# pse84_a0 register map
Vendor: Infineon Technologies; Series: PSE84_A0; File version: 1.0
CPU: CM33 r0p1, little endian, MPU, FPU, VTOR, 3 interrupt priority bits
Registers are 32-bit, read-write, reset 0x0 unless marked. A register's access mark holds for its fields unless they carry their own. Offsets are from the block's base; [hi:lo] are bit positions; lines under a group give offsets from that group; {n}, {i} and the like mark numbered series; 'fields as' and 'values as' point back to an identical list; <NAME> marks a mode.

## USBHS (part 6 of 7) — Regmap for both Subsystem and Controller IP
Base 0x44900000
0x00 DWC_OTG_INTREG group — Internal register map
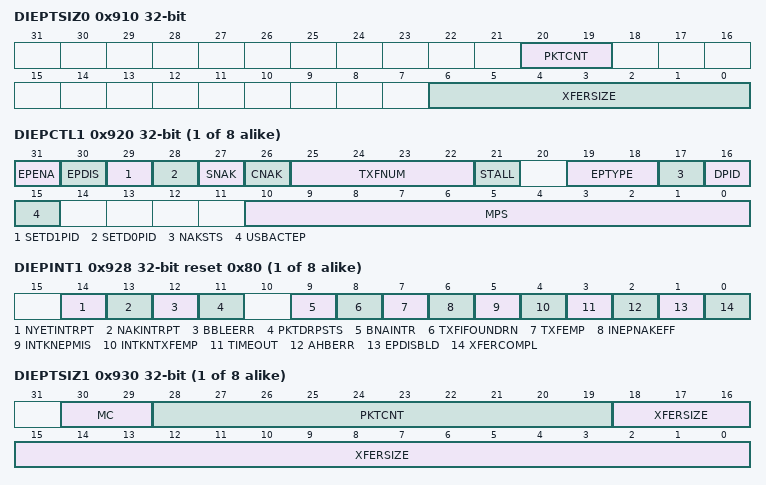
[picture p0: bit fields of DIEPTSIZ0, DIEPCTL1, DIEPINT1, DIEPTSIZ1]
  0x910 DIEPTSIZ0 — The application must modify this register before enabling endpoint 0. Once endpoint 0 is enabled using Endpoint Enable bit of the Device Control Endpoint 0 Control registers (DIEPCTL0.EPEna/DOEPCTL0.EPEna), the core modifies this register. The application can only read this register once the core has cleared the Endpoint Enable bit. Nonzero endpoints use the registers for endpoints 115. When Scatter/Gather DMA mode is enabled, this register must not be programmed by the application. If the application reads this register when Scatter/Gather DMA mode is enabled, the core returns all zeros.
    [20:19] PKTCNT — Packet Count (PktCnt) Indicates the total number of USB packets that constitute the Transfer Size amount of data for endpoint 0. - IN Endpoints : This field is decremented every time a packet (maximum size or short packet) is read from the TxFIFO. - OUT Endpoints: This field is decremented every time a packet (maximum size or short packet) is written to the RxFIFO.
    [6:0] XFERSIZE — Transfer Size (XferSize) This field contains the transfer size in bytes for the current endpoint. The transfer size (XferSize) = Sum of buffer sizes across all descriptors in the list for the endpoint. In Buffer DMA, the core only interrupts the application after it has exhausted the transfer size amount of data. The transfer size can be set to the maximum packet size of the endpoint, to be interrupted at the end of each packet. - IN Endpoints: The core decrements this field every time a packet from the external memory is written to the TxFIFO. - OUT Endpoints: The core decrements this field every time a packet is read from the RxFIFO and written to the external memory.
  0x914 DIEPDMA0 reset not defined — This register contains the DMA Address for the IN Endpoint 0 of the Device controller.
    [31:0] DMAADDR — DMAAddr This field holds the start address of the external memory for storing or fetching endpoint data. Note: For control endpoints, this field stores control OUT data packets as well as SETUP transaction data packets. When more than three SETUP packets are received back-to-back, the SETUP data packet in the memory is overwritten. This register is incremented on every AHB transaction. The application can give only a DWORD-aligned address. When Scatter/Gather DMA mode is not enabled, the application programs the start address value in this field. When Scatter/Gather DMA mode is enabled, this field indicates the base pointer for the descriptor list.
  0x918 DTXFSTS0 ro reset 0x100 — This register contains information about the IN Endpoint Transmit FIFO of the Device controller.
    [15:0] INEPTXFSPCAVAIL
  0x91C DIEPDMAB0 ro reset not defined — This register contains the DMA Buffer Address for the IN Endpoint 0 of the Device controller.
    [31:0] DMABUFFERADDR
  {0x900+0x20*j} DIEPCTL{j} (j=1..8) — This register is used to control the characteristics of Endpoint {j}. Note: This register exists for an endpoint i if the OTG_EP_DIR_i parameter is 0 or 1 for that endpoint.
    [31] EPENA — Endpoint Enable (EPEna) Applies to IN and OUT endpoints. - When Scatter/Gather DMA mode is enabled, -- For IN endpoints this bit indicates that the descriptor structure and data buffer with data ready to transmit is setup. -- For OUT endpoint it indicates that the descriptor structure and data buffer to receive data is setup. - When Scatter/Gather DMA mode is enabled such as for buffer-pointer based DMA mode: -- For IN endpoints, this bit indicates that data is ready to be transmitted on the endpoint. -- For OUT endpoints, this bit indicates that the application has allocated the memory to start receiving data from the USB. - The core clears this bit before setting any of the following interrupts on this endpoint: -- SETUP Phase Done -- Endpoint Disabled -- Transfer Completed Note: For control endpoints in DMA mode, this bit must be set to be able to transfer SETUP data packets in memory.
      1=ACTIVE (Enable Endpoint); 0=INACTIVE (No Action)
    [30] EPDIS — Endpoint Disable (EPDis) Applies to IN and OUT endpoints. The application sets this bit to stop transmitting/receiving data on an endpoint, even before the transfer for that endpoint is complete. The application must wait for the Endpoint Disabled interrupt before treating the endpoint as disabled. The core clears this bit before setting the Endpoint Disabled interrupt. The application must set this bit only if Endpoint Enable is already set for this endpoint.
      1=ACTIVE (Disable Endpoint); 0=INACTIVE (No Action)
    [29] SETD1PID wo — SetD1PID - Set DATA1 PID (SetD1PID) -- Applies to interrupt and bulk IN and OUT endpoints only. -- Writing to this field sets the Endpoint Data PID (DPID) field in this register to DATA1. -- This field is applicable both for Scatter-Gather DMA mode and non Scatter-Gather DMA mode. - Set odd (micro)Frame (SetOddFr) -- Applies to isochronous IN and OUT endpoints only. -- Writing to this field sets the even and odd (micro)Frame (EO_FrNum) field to odd (micro)Frame. -- This field is not applicable for Scatter-Gather DMA mode.
      0=DISABLED (Disables Set DATA1 PID); 1=ENABLED (Enables Set DATA1 PID)
    [28] SETD0PID wo
      0=DISABLED (Disables Set DATA0 PID); 1=ENABLED (Endpoint Data PID to DATA0))
    [27] SNAK wo — Set NAK (SNAK) A write to this bit sets the NAK bit for the endpoint. Using this bit, the application can control the transmission of NAK handshakes on an endpoint. The core can also Set this bit for an endpoint after a SETUP packet is received on that endpoint.
      1=ACTIVE (Set NAK); 0=INACTIVE (No Set NAK)
    [26] CNAK wo — Clear NAK (CNAK) A write to this bit clears the NAK bit for the endpoint.
      1=ACTIVE (Clear NAK); 0=INACTIVE (No Clear NAK)
    [25:22] TXFNUM — TxFIFO Number (TxFNum) Shared FIFO Operation non-periodic endpoints must set this bit to zero. Periodic endpoints must map this to the corresponding Periodic TxFIFO number. - 4'h0: Non-Periodic TxFIFO - Others: Specified Periodic TxFIFO.number Note: An interrupt IN endpoint can be configured as a non-periodic endpoint for applications such as mass storage. The core treats an IN endpoint as a non-periodic endpoint if the TxFNum field is set to 0. Otherwise, a separate periodic FIFO must be allocated for an interrupt IN endpoint, and the number of this FIFO must be programmed into the TxFNum field. Configuring an interrupt IN endpoint as a non-periodic endpoint saves the extra periodic FIFO area. Dedicated FIFO Operation: These bits specify the FIFO number associated with this endpoint. Each active IN endpoint must be programmed to a separate FIFO number. This field is valid only for IN endpoints.
      {v}=TXFIFO{v} (v=0..15)
    [21] STALL — STALL Handshake (Stall) Applies to non-control, non-isochronous IN and OUT endpoints only. The application sets this bit to stall all tokens from the USB host to this endpoint. If a NAK bit, Global Non-periodic IN NAK, or Global OUT NAK is set along with this bit, the STALL bit takes priority. Only the application can clear this bit, never the core. Applies to control endpoints only. The application can only set this bit, and the core clears it, when a SETUP token is received for this endpoint. If a NAK bit, Global Non-periodic IN NAK, or Global OUT NAK is set along with this bit, the STALL bit takes priority. Irrespective of this bit's setting, the core always responds to SETUP data packets with an ACK handshake.
      1=ACTIVE (STALL All Active Tokens); 0=INACTIVE (STALL All non-active tokens)
    [19:18] EPTYPE — Endpoint Type (EPType) This is the transfer type supported by this logical endpoint. - 2'b00: Control - 2'b01: Isochronous - 2'b10: Bulk - 2'b11: Interrupt
      2=BULK; 0=CONTROL; 3=INTERRUP (Interrupt); 1=ISOCHRONOUS
    [17] NAKSTS ro — NAK Status (NAKSts) Indicates the following: - 1'b0: The core is transmitting non-NAK handshakes based on the FIFO status. - 1'b1: The core is transmitting NAK handshakes on this endpoint. When either the application or the core sets this bit: - The core stops receiving any data on an OUT endpoint, even if there is space in the RxFIFO to accommodate the incoming packet. - For non-isochronous IN endpoints: The core stops transmitting any data on an IN endpoint, even if there data is available in the TxFIFO. - For isochronous IN endpoints: The core sends out a zero-length data packet, even if there data is available in the TxFIFO. Irrespective of this bit's setting, the core always responds to SETUP data packets with an ACK handshake.
      1=NAK (The core is transmitting NAK handshakes on this endpoint); 0=NONNAK (The core is transmitting non-NAK handshakes based on the FIFO status)
    [16] DPID ro
      0=DATA0EVENFRM (DATA0 or Even Frame); 1=DATA1ODDFRM (DATA1 or Odd Frame)
    [15] USBACTEP — USB Active Endpoint (USBActEP) Indicates whether this endpoint is active in the current configuration and interface. The core clears this bit for all endpoints (other than EP 0) after detecting a USB reset. After receiving the SetConfiguration and SetInterface commands, the application must program endpoint registers accordingly and set this bit.
      0=DISABLED (Not Active); 1=ENABLED (USB Active Endpoint)
    [10:0] MPS — Maximum Packet Size (MPS) The application must program this field with the maximum packet size for the current logical endpoint. This value is in bytes.
  {0x908+0x20*j} DIEPINT{j} reset 0x80 (j=1..8) — This register contains the interrupts for the IN Endpoint {j} of the Device controller. Note: This register exists for an endpoint i if the OTG_EP_DIR_i parameter is 0 or 1 for that endpoint.
    [14] NYETINTRPT — NYET Interrupt (NYETIntrpt) The core generates this interrupt when a NYET response is transmitted for a non isochronous OUT endpoint.
      1=ACTIVE (NYET Interrupt); 0=INACTIVE (No NYET interrupt)
    [13] NAKINTRPT — NAK Interrupt (NAKInterrupt) The core generates this interrupt when a NAK is transmitted or received by the device. In case of isochronous IN endpoints the interrupt gets generated when a zero length packet is transmitted due to un-availability of data in the TXFifo.
      1=ACTIVE (NAK Interrupt); 0=INACTIVE (No NAK interrupt)
    [12] BBLEERR — NAK Interrupt (BbleErr) The core generates this interrupt when babble is received for the endpoint.
      1=ACTIVE (BbleErr interrupt); 0=INACTIVE (No interrupt)
    [11] PKTDRPSTS — Packet Drop Status (PktDrpSts) This bit indicates to the application that an ISOC OUT packet has been dropped. This bit does not have an associated mask bit and does not generate an interrupt. Dependency: This bit is valid in non Scatter/Gather DMA mode when periodic transfer interrupt feature is selected.
      1=ACTIVE (Packet Drop Status interrupt); 0=INACTIVE (No interrupt)
    [9] BNAINTR — BNA (Buffer Not Available) Interrupt (BNAIntr) This bit is valid only when Scatter/Gather DMA mode is enabled. The core generates this interrupt when the descriptor accessed is not ready for the Core to process, such as Host busy or DMA done.
      1=ACTIVE (BNA interrupt); 0=INACTIVE (No BNA interrupt)
    [8] TXFIFOUNDRN — Fifo Underrun (TxfifoUndrn) Applies to IN endpoints Only This bit is valid only If thresholding is enabled. The core generates this interrupt when it detects a transmit FIFO underrun condition for this endpoint.
      1=ACTIVE (TxFIFO Underrun interrupt); 0=INACTIVE (No Tx FIFO Underrun interrupt)
    [7] TXFEMP ro — Transmit FIFO Empty (TxFEmp) This bit is valid only for IN endpoints This interrupt is asserted when the TxFIFO for this endpoint is either half or completely empty. The half or completely empty status is determined by the TxFIFO Empty Level bit in the Core AHB Configuration register (GAHBCFG.NPTxFEmpLvl)).
      1=ACTIVE (Transmit FIFO Empty interrupt); 0=INACTIVE (No Transmit FIFO Empty interrupt)
    [6] INEPNAKEFF — IN Endpoint NAK Effective (INEPNakEff) Applies to periodic IN endpoints only. This bit can be cleared when the application clears the IN endpoint NAK by writing to DIEPCTLn.CNAK. This interrupt indicates that the core has sampled the NAK bit Set (either by the application or by the core). The interrupt indicates that the IN endpoint NAK bit Set by the application has taken effect in the core. This interrupt does not guarantee that a NAK handshake is sent on the USB. A STALL bit takes priority over a NAK bit.
      1=ACTIVE (IN Endpoint NAK Effective interrupt); 0=INACTIVE (No Endpoint NAK Effective interrupt)
    [5] INTKNEPMIS — IN Token Received with EP Mismatch (INTknEPMis) Applies to non-periodic IN endpoints only. Indicates that the data in the top of the non-periodic TxFIFO belongs to an endpoint other than the one for which the IN token was received. This interrupt is asserted on the endpoint for which the IN token was received.
      1=ACTIVE (IN Token Received with EP Mismatch interrupt); 0=INACTIVE (No IN Token Received with EP Mismatch interrupt)
    [4] INTKNTXFEMP — IN Token Received When TxFIFO is Empty (INTknTXFEmp) Applies to non-periodic IN endpoints only. Indicates that an IN token was received when the associated TxFIFO (periodic/non-periodic) was empty. This interrupt is asserted on the endpoint for which the IN token was received.
      1=ACTIVE (IN Token Received Interrupt); 0=INACTIVE (No IN Token Received interrupt)
    [3] TIMEOUT — Timeout Condition (TimeOUT) - In shared TX FIFO mode, applies to non-isochronous IN endpoints only. - In dedicated FIFO mode, applies only to Control IN endpoints. - In Scatter/Gather DMA mode, the TimeOUT interrupt is not asserted. Indicates that the core has detected a timeout condition on the USB for the last IN token on this endpoint.
      1=ACTIVE (Timeout interrupt); 0=INACTIVE (No Timeout interrupt)
    [2] AHBERR — AHB Error (AHBErr) Applies to IN and OUT endpoints. This is generated only in Internal DMA mode when there is an AHB error during an AHB read/write. The application can read the corresponding endpoint DMA address register to get the error address. For details, see 'AHB Error Handling' in the Programming Guide.
      1=ACTIVE (AHB Error interrupt); 0=INACTIVE (No AHB Error Interrupt)
    [1] EPDISBLD — Endpoint Disabled Interrupt (EPDisbld) Applies to IN and OUT endpoints. This bit indicates that the endpoint is disabled per the application's request.
      1=ACTIVE (Endpoint Disabled Interrupt); 0=INACTIVE (No Endpoint Disabled Interrupt)
    [0] XFERCOMPL — Transfer Completed Interrupt (XferCompl) Applies to IN and OUT endpoints. - When Scatter/Gather DMA mode is enabled -- For IN endpoint this field indicates that the requested data from the descriptor is moved from external system memory to internal FIFO. -- For OUT endpoint this field indicates that the requested data from the internal FIFO is moved to external system memory. This interrupt is generated only when the corresponding endpoint descriptor is closed, and the IOC bit for the corresponding descriptor is set. - When Scatter/Gather DMA mode is disabled, this field indicates that the programmed transfer is complete on the AHB as well as on the USB, for this endpoint.
      1=ACTIVE (Transfer Complete Interrupt); 0=INACTIVE (No Transfer Complete Interrupt)
  {0x910+0x20*j} DIEPTSIZ{j} (j=1..8) — This register reflects the Transfer Size of the IN Endpoint {j} of the Device controller. Note: This register exists for an endpoint i if the OTG_EP_DIR_i parameter is 0 or 1 for that endpoint.
    [30:29] MC — MC Applies to IN endpoints only. For periodic IN endpoints, this field indicates the number of packets that must be transmitted per microframe on the USB. The core uses this field to calculate the data PID for isochronous IN endpoints. - 2'b01: 1 packet - 2'b10: 2 packets - 2'b11: 3 packets For non-periodic IN endpoints, this field is valid only in Internal DMA mode. It specifies the number of packets the core must fetchfor an IN endpoint before it switches to the endpoint pointed to by the Next Endpoint field of the Device Endpoint-n Control register (DIEPCTLn.NextEp)
      1=PACKETONE (1 packet); 3=PACKETTHREE (3 packets); 2=PACKETTWO (2 packets)
    [28:19] PKTCNT — Packet Count (PktCnt) Indicates the total number of USB packets that constitute the Transfer Size amount of data for endpoint 0. This field is decremented every time a packet (maximum size or short packet) is read from the TxFIFO.
    [18:0] XFERSIZE — Transfer Size (XferSize) Indicates the transfer size in bytes for endpoint 0. The core interrupts the application only after it has exhausted the transfer size amount of data. The transfer size can be Set to the maximum packet size of the endpoint, to be interrupted at the end of each packet. The core decrements this field every time a packet from the external memory is written to the TxFIFO.
  {0x914+0x20*j} DIEPDMA{j} reset not defined (j=1..8) — This register contains the DMA Address for the IN Endpoint {j} of the Device controller. Note: This register exists for an endpoint i if the OTG_EP_DIR_i parameter is 0 or 1 for that endpoint.
    [31:0] DMAADDR — Holds the start address of the external memory for storing or fetching endpoint data. Note: For control endpoints, this field stores control OUT data packets as well as SETUP transaction data packets. When more than three SETUP packets are received back-to-back, the SETUP data packet in the memory is overwritten. This register is incremented on every AHB transaction. The application can give only a DWORD-aligned address. - When Scatter/Gather DMA mode is not enabled, the application programs the start address value in this field. - When Scatter/Gather DMA mode is enabled, this field indicates the base pointer for the descriptor list.
  {0x918+0x20*j} DTXFSTS{j} ro reset 0x100 (j=1..8) — This register reflects the status of the IN Endpoint Transmit FIFO Status Register {j} of the Device controller. Note: This register exists for an endpoint i if the OTG_EP_DIR_i parameter is 0 or 1 for that endpoint.
    [15:0] INEPTXFSPCAVAIL
  {0x91C+0x20*j} DIEPDMAB{j} ro reset not defined (j=1..8) — This register contains the DMA Buffer Address of the IN Endpoint {j} of the Device controller. Note: This register exists for an endpoint i if the OTG_EP_DIR_i parameter is 0 or 1 for that endpoint.
    [31:0] DMABUFFERADDR
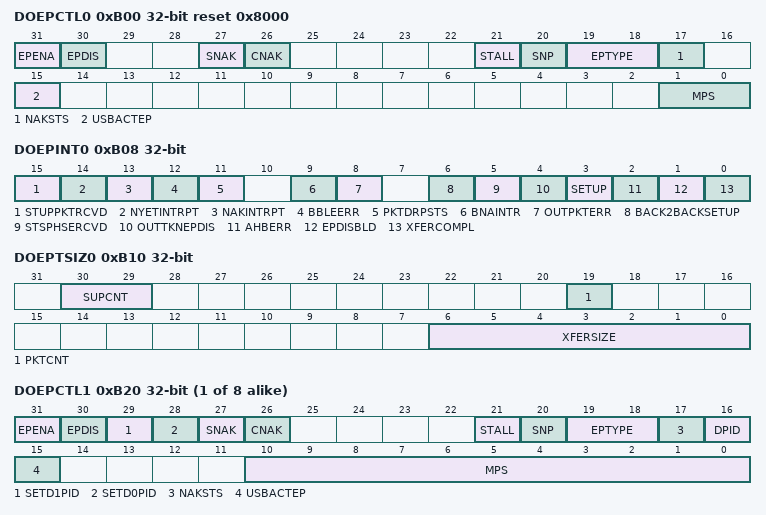
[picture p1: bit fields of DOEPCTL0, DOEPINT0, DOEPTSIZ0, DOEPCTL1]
  0xB00 DOEPCTL0 reset 0x8000 — This register is used to control the characteristics of the OUT Endpoint 0 of the Device controller.
    [31] EPENA — Endpoint Enable (EPEna) - When Scatter/Gather DMA mode is enabled, for OUT endpoints this bit indicates that the descriptor structure and data buffer to receive data is setup. - When Scatter/Gather DMA mode is disabled (such as for buffer-pointer based DMA mode)this bit indicates that the application has allocated the memory to start receiving data from the USB. - The core clears this bit before setting any of the following interrupts on this endpoint: -- SETUP Phase Done -- Endpoint Disabled -- Transfer Completed Note: In DMA mode, this bit must be set for the core to transfer SETUP data packets into memory and it will not be cleared on Transfer Completed interrupt of SETUP packet.
      1=ACTIVE (Enable Endpoint); 0=INACTIVE (No action)
    [30] EPDIS ro — Endpoint Disable (EPDis) The application cannot disable control OUT endpoint 0.
      0=INACTIVE (No Endpoint disable)
    [27] SNAK wo — Set NAK (SNAK) A write to this bit sets the NAK bit for the endpoint. Using this bit, the application can control the transmission of NAK handshakes on an endpoint. The core can also set bit on a Transfer Completed interrupt, or after a SETUP is received on the endpoint.
      0=NOSET (No action); 1=SET (Set NAK)
    [26] CNAK wo — Clear NAK (CNAK) A write to this bit clears the NAK bit for the endpoint.
      1=CLEAR (Clear NAK); 0=NOCLEAR (No action)
    [21] STALL — STALL Handshake (Stall) The application can only set this bit, and the core clears it, when a SETUP token is received for this endpoint. If a NAK bit or Global OUT NAK is Set along with this bit, the STALL bit takes priority. Irrespective of this bit's setting, the core always responds to SETUP data packets with an ACK handshake.
      1=ACTIVE (Stall Handshake); 0=INACTIVE (No Stall)
    [20] SNP
      0=RSVD0SnpDOEPCTL0 (N/A); 1=RSVD1SnpDOEPCTL0 (N/A)
    [19:18] EPTYPE ro — Endpoint Type (EPType) Hardcoded to 2'b00 for control.
      0=ACTIVE (Endpoint Control 0)
    [17] NAKSTS ro — NAK Status (NAKSts) Indicates the following: - 1'b0: The core is transmitting non-NAK handshakes based on the FIFO status. - 1'b1: The core is transmitting NAK handshakes on this endpoint. When either the application or the core sets this bit, the core stops receiving data, even If there is space in the RxFIFO to accommodate the incoming packet. Irrespective of this bit's setting, the core always responds to SETUP data packets with an ACK handshake.
      1=ACTIVE (The core is transmitting NAK handshakes on this endpoint); 0=INACTIVE (The core is transmitting non-NAK handshakes based on the FIFO status)
    [15] USBACTEP ro — USB Active Endpoint (USBActEP) This bit is always set to 1, indicating that a control endpoint 0 is always active in all configurations and interfaces.
      1=ACTIVE (USB Active Endpoint 0)
    [1:0] MPS ro — Maximum Packet Size (MPS) The maximum packet size for control OUT endpoint 0 is the same as what is programmed in control IN Endpoint 0. - 2'b00: 64 bytes - 2'b01: 32 bytes - 2'b10: 16 bytes - 2'b11: 8 bytes
      2=BYTE16 (16 bytes); 1=BYTE32 (32 bytes); 0=BYTE64 (64 bytes); 3=BYTE8 (8 bytes)
  0xB08 DOEPINT0 — This register contains the interrupts for the OUT Endpoint 0 of the Device controller.
    [15] STUPPKTRCVD — Setup Packet Received Applicable for Control OUT Endpoints in only in the Buffer DMA Mode Set by the controller, this bit indicates that this buffer holds 8 bytes of setup data. There is only one Setup packet per buffer. On receiving a Setup packet, the controller closes the buffer and disables the corresponding endpoint. The application has to re-enable the endpoint to receive any OUT data for the Control Transfer and reprogram the buffer start address. Note: Because of the above behavior, the controller can receive any number of back to back setup packets and one buffer for every setup packet is used. - 1'b0: No Setup packet received - 1'b1: Setup packet received Reset: 1'b0
      0=NOT_RCVD (No Setup packet received); 1=RCVD (Setup packet received)
    [14] NYETINTRPT — NYET Interrupt (NYETIntrpt) The core generates this interrupt when a NYET response is transmitted for a non isochronous OUT endpoint.
      1=ACTIVE (NYET Interrupt); 0=INACTIVE (No NYET interrupt)
    [13] NAKINTRPT — NAK Interrupt (NAKInterrupt) The core generates this interrupt when a NAK is transmitted or received by the device. In case of isochronous IN endpoints the interrupt gets generated when a zero length packet is transmitted due to un-availability of data in the TXFifo.
      1=ACTIVE (NAK Interrupt); 0=INACTIVE (No NAK interrupt)
    [12] BBLEERR — NAK Interrupt (BbleErr) The core generates this interrupt when babble is received for the endpoint.
      1=ACTIVE (BbleErr interrupt); 0=INACTIVE (No BbleErr interrupt)
    [11] PKTDRPSTS — Packet Drop Status (PktDrpSts) This bit indicates to the application that an ISOC OUT packet has been dropped. This bit does not have an associated mask bit and does not generate an interrupt. Dependency: This bit is valid in non Scatter/Gather DMA mode when periodic transfer interrupt feature is selected.
      values as DWC_OTG_INTREG.DIEPINT1.PKTDRPSTS
    [9] BNAINTR — BNA (Buffer Not Available) Interrupt (BNAIntr) This bit is valid only when Scatter/Gather DMA mode is enabled. The core generates this interrupt when the descriptor accessed is not ready for the core to process, such as Host busy or DMA done.
      1=ACTIVE (BNA interrupt); 0=INACTIVE (No BNA interrupt)
    [8] OUTPKTERR — OUT Packet Error (OutPktErr) Applies to OUT endpoints Only This interrupt is valid only when thresholding is enabled. This interrupt is asserted when the core detects an overflow or a CRC error for non-Isochronous OUT packet.
      1=ACTIVE (OUT Packet Error); 0=INACTIVE (No OUT Packet Error)
    [6] BACK2BACKSETUP — Back-to-Back SETUP Packets Received (Back2BackSETup) Applies to Control OUT endpoints only. This bit indicates that the core has received more than three back-to-back SETUP packets for this particular endpoint. For information about handling this interrupt,
      1=ACTIVE (Back-to-Back SETUP Packets Received); 0=INACTIVE (No Back-to-Back SETUP Packets Received)
    [5] STSPHSERCVD — Status Phase Received for Control Write (StsPhseRcvd) This interrupt is valid only for Control OUT endpoints. This interrupt is generated only after the core has transferred all the data that the host has sent during the data phase of a control write transfer, to the system memory buffer. The interrupt indicates to the application that the host has switched from data phase to the status phase of a Control Write transfer. The application can use this interrupt to ACK or STALL the Status phase, after it has decoded the data phase. This is applicable only in case of Scatter Gather DMA mode.
      1=ACTIVE (Status Phase Received for Control Write); 0=INACTIVE (No Status Phase Received for Control Write)
    [4] OUTTKNEPDIS — OUT Token Received When Endpoint Disabled (OUTTknEPdis) Applies only to control OUT endpoints. Indicates that an OUT token was received when the endpoint was not yet enabled. This interrupt is asserted on the endpoint for which the OUT token was received.
      1=ACTIVE (OUT Token Received When Endpoint Disabled); 0=INACTIVE (No OUT Token Received When Endpoint Disabled)
    [3] SETUP — SETUP Phase Done (SetUp) Applies to control OUT endpoints only. Indicates that the SETUP phase for the control endpoint is complete and no more back-to-back SETUP packets were received for the current control transfer. On this interrupt, the application can decode the received SETUP data packet.
      1=ACTIVE (SETUP Phase Done); 0=INACTIVE (No SETUP Phase Done)
    [2] AHBERR — AHB Error (AHBErr) Applies to IN and OUT endpoints. This is generated only in Internal DMA mode when there is an AHB error during an AHB read/write. The application can read the corresponding endpoint DMA address register to get the error address. For details, see 'AHB Error Handling' section in the Programming Guide.
      values as DWC_OTG_INTREG.DIEPINT1.AHBERR
    [1] EPDISBLD — Endpoint Disabled Interrupt (EPDisbld) Applies to IN and OUT endpoints. This bit indicates that the endpoint is disabled per the application's request.
      values as DWC_OTG_INTREG.DIEPINT1.EPDISBLD
    [0] XFERCOMPL — Transfer Completed Interrupt (XferCompl) Applies to IN and OUT endpoints. When Scatter/Gather DMA mode is enabled - For IN endpoint this field indicates that the requested data from the descriptor is moved from external system memory to internal FIFO. - For OUT endpoint this field indicates that the requested data from the internal FIFO is moved to external system memory. This interrupt is generated only when the corresponding endpoint descriptor is closed, and the IOC bit for the corresponding descriptor is Set. Note: In DMA mode, this bit must be set for the core to transfer SETUP data packets into memory. When Scatter/Gather DMA mode is disabled, this field indicates that the programmed transfer is complete on the AHB as well as on the USB, for this endpoint.
      values as DWC_OTG_INTREG.DIEPINT1.XFERCOMPL
  0xB10 DOEPTSIZ0 — This register contains the Transfer Size for the OUT Endpoint 0 of the Device controller.
    [30:29] SUPCNT — SETUP Packet Count (SUPCnt) This field specifies the number of back-to-back SETUP data packets the endpoint can receive. - 2'b01: 1 packet - 2'b10: 2 packets - 2'b11: 3 packets
      1=ONEPACKET (1 packet); 3=THREEPACKET (3 packets); 2=TWOPACKET (2 packets)
    [19] PKTCNT — Packet Count (PktCnt) This field is decremented to zero after a packet is written into the RxFIFO.
    [6:0] XFERSIZE — Transfer Size (XferSize) Indicates the transfer size in bytes for endpoint 0. The core interrupts the application only after it has exhausted the transfer size amount of data. The transfer size can be Set to the maximum packet size of the endpoint, to be interrupted at the end of each packet. The core decrements this field every time a packet is read from the RxFIFO and written to the external memory.
  {0xB14+0x20*j} DOEPDMA{j} reset not defined (j=0..8) — This register contains the DMA Address for the OUT Endpoint {j} of the Device controller.
    fields as DWC_OTG_INTREG.DIEPDMA1
  {0xB1C+0x20*j} DOEPDMAB{j} ro reset not defined (j=0..8) — This register contains the DMA Buffer Address for the OUT Endpoint {j} of the Device controller.
    [31:0] DMABUFFERADDR
  {0xB00+0x20*j} DOEPCTL{j} (j=1..8) — This register is used to control the characteristics of OUT Endpoint {j} of the Device controller.
    [31] EPENA — Endpoint Enable (EPEna) Applies to IN and OUT endpoints. When Scatter/Gather DMA mode is enabled, - For IN endpoints this bit indicates that the descriptor structure and data buffer with data ready to transmit is setup. - For OUT endpoint it indicates that the descriptor structure and data buffer to receive data is setup. When Scatter/Gather DMA mode is enabled such as for buffer-pointer based DMA mode: - For IN endpoints, this bit indicates that data is ready to be transmitted on the endpoint. - For OUT endpoints, this bit indicates that the application has allocated the memory to start receiving data from the USB. The core clears this bit before setting any of the following interrupts on this endpoint: - SETUP Phase Done - Endpoint Disabled - Transfer Completed Note: For control endpoints in DMA mode, this bit must be set for the controller to transfer SETUP data packets to the memory. This bit will not be cleared on Transfer Completed interrupt of the SETUP packet.
      1=ACTIVE (Enable Endpoint); 0=INACTIVE (No Action)
    [30] EPDIS — Endpoint Disable (EPDis) Applies to IN and OUT endpoints. The application sets this bit to stop transmitting/receiving data on an endpoint, even before the transfer for that endpoint is complete. The application must wait for the Endpoint Disabled interrupt before treating the endpoint as disabled. The core clears this bit before setting the Endpoint Disabled interrupt. The application must set this bit only if Endpoint Enable is already set for this endpoint.
      1=ACTIVE (Disable Endpoint); 0=INACTIVE (No Action)
    [29] SETD1PID wo — Set DATA1 PID (SetD1PID) - Applies to interrupt and bulk IN and OUT endpoints only. - Writing to this field sets the Endpoint Data PID (DPID) field in this register to DATA1. - This field is applicable both for scatter-gather DMA mode and non scatter-gather DMA mode. Reset: 1'b0 Set Odd (micro)frame (SetOddFr) - Applies to isochronous IN and OUT endpoints only. - Writing to this field sets the even and odd (micro)frame (EO_FrNum) field to odd (micro)frame. Reset: 1'b0
      0=DISABLED (Disables Set DATA1 PID or Do not force Odd Frame); 1=ENABLED (Set Endpoint Data PID to DATA1 or Sets EO_FrNum field to odd <ct:DWC_DESIGN_ID==1>frame</ct><ct:DWC_DESIGN_ID!=1>(micro)Frame</ct>)
    [28] SETD0PID wo
      0=DISABLED (Disables Set DATA0 PID or Do not force Even Frame); 1=ENABLED (Set Endpoint Data PID to DATA0 or Sets EO_FrNum field to odd <ct:DWC_DESIGN_ID==1>frame</ct><ct:DWC_DESIGN_ID!=1>(micro)Frame</ct>)
    [27] SNAK wo — Set NAK (SNAK) A write to this bit sets the NAK bit for the endpoint. Using this bit, the application can control the transmission of NAK handshakes on an endpoint. The core can also set this bit for an endpoint after a SETUP packet is received on that endpoint.
      1=ACTIVE (Set NAK); 0=INACTIVE (No Set NAK)
    [26] CNAK wo — Clear NAK (CNAK) A write to this bit clears the NAK bit for the endpoint.
      1=ACTIVE (Clear NAK); 0=INACTIVE (No Clear NAK)
    [21] STALL — STALL Handshake (Stall) Applies to non-control, non-isochronous IN and OUT endpoints only. The application sets this bit to stall all tokens from the USB host to this endpoint. If a NAK bit, Global Non-periodic IN NAK, or Global OUT NAK is set along with this bit, the STALL bit takes priority. Only the application can clear this bit, never the core. Applies to control endpoints only. The application can only set this bit, and the core clears it, when a SETUP token is received for this endpoint. If a NAK bit, Global Non-periodic IN NAK, or Global OUT NAK is set along with this bit, the STALL bit takes priority. Irrespective of this bit's setting, the core always responds to SETUP data packets with an ACK handshake.
      values as DWC_OTG_INTREG.DIEPCTL1.STALL
    [20] SNP
      0=RSVD0SnpDOEPCTL{j} (N/A); 1=RSVD1SnpDOEPCTL{j} (N/A)
    [19:18] EPTYPE — Endpoint Type (EPType) This is the transfer type supported by this logical endpoint. - 2'b00: Control - 2'b01: Isochronous - 2'b10: Bulk - 2'b11: Interrupt
      2=BULK; 0=CONTROL; 3=INTERRUPT; 1=ISOCHRONOUS
    [17] NAKSTS ro — NAK Status (NAKSts) Indicates the following: - 1'b0: The core is transmitting non-NAK handshakes based on the FIFO status. - 1'b1: The core is transmitting NAK handshakes on this endpoint. When either the application or the core sets this bit: - The core stops receiving any data on an OUT endpoint, even if there is space in the RxFIFO to accommodate the incoming packet. - For non-isochronous IN endpoints: The core stops transmitting any data on an IN endpoint, even if there data is available in the TxFIFO. - For isochronous IN endpoints: The core sends out a zero-length data packet, even if there data is available in the TxFIFO. Irrespective of this bit's setting, the core always responds to SETUP data packets with an ACK handshake.
      values as DWC_OTG_INTREG.DIEPCTL1.NAKSTS
    [16] DPID ro
      1=ACTIVE (Endpoint Data PID active); 0=INACTIVE (Endpoint Data PID not active)
    [15] USBACTEP — USB Active Endpoint (USBActEP) Indicates whether this endpoint is active in the current configuration and interface. The core clears this bit for all endpoints (other than EP 0) after detecting a USB reset. After receiving the SetConfiguration and SetInterface commands, the application must program endpoint registers accordingly and set this bit.
      0=DISABLED (Not Active); 1=ENABLED (USB Active Endpoint)
    [10:0] MPS — Maximum Packet Size (MPS) The application must program this field with the maximum packet size for the current logical endpoint. This value is in bytes.
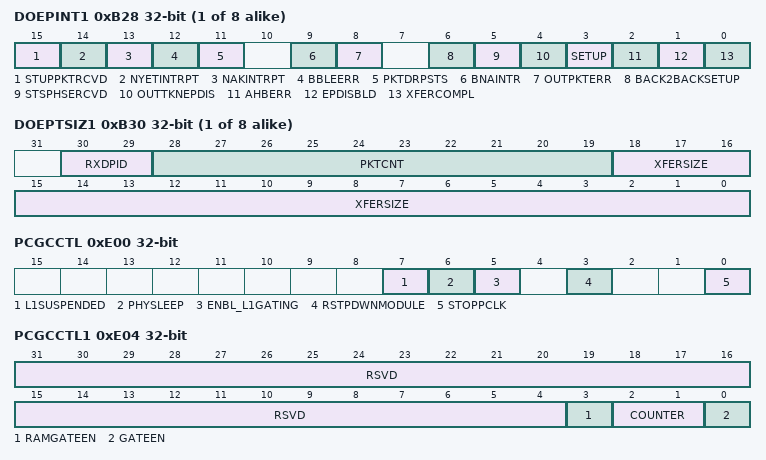
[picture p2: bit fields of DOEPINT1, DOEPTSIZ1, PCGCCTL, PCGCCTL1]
  {0xB08+0x20*j} DOEPINT{j} (j=1..8) — This register contains the interrupts for the OUT Endpoint {j} of the Device controller.
    [15] STUPPKTRCVD — Setup Packet Received Applicable for Control OUT Endpoints in only in the Buffer DMA Mode Set by the controller, this bit indicates that this buffer holds 8 bytes of setup data. There is only one Setup packet per buffer. On receiving a Setup packet, the controller closes the buffer and disables the corresponding endpoint. The application has to re-enable the endpoint to receive any OUT data for the Control Transfer and reprogram the buffer start address. Note: Because of the above behavior, the controller can receive any number of back to back setup packets and one buffer for every setup packet is used. - 1'b0: No Setup packet received - 1'b1: Setup packet received Reset: 1'b0
      values as DWC_OTG_INTREG.DOEPINT0.STUPPKTRCVD
    [14] NYETINTRPT — NYET Interrupt (NYETIntrpt) The core generates this interrupt when a NYET response is transmitted for a non isochronous OUT endpoint.
      1=ACTIVE (NYET Interrupt); 0=INACTIVE (No NYET interrupt)
    [13] NAKINTRPT — NAK Interrupt (NAKInterrupt) The core generates this interrupt when a NAK is transmitted or received by the device. In case of isochronous IN endpoints the interrupt gets generated when a zero length packet is transmitted due to un-availability of data in the TXFifo.
      1=ACTIVE (NAK Interrupt); 0=INACTIVE (No NAK interrupt)
    [12] BBLEERR — NAK Interrupt (BbleErr) The core generates this interrupt when babble is received for the endpoint.
      values as DWC_OTG_INTREG.DOEPINT0.BBLEERR
    [11] PKTDRPSTS — Packet Drop Status (PktDrpSts) This bit indicates to the application that an ISOC OUT packet has been dropped. This bit does not have an associated mask bit and does not generate an interrupt. Dependency: This bit is valid in non Scatter/Gather DMA mode when periodic transfer interrupt feature is selected.
      values as DWC_OTG_INTREG.DIEPINT1.PKTDRPSTS
    [9] BNAINTR — BNA (Buffer Not Available) Interrupt (BNAIntr) This bit is valid only when Scatter/Gather DMA mode is enabled. The core generates this interrupt when the descriptor accessed is not ready for the Core to process, such as Host busy or DMA done
      1=ACTIVE (BNA interrupt); 0=INACTIVE (No BNA interrupt)
    [8] OUTPKTERR — OUT Packet Error (OutPktErr) Applies to OUT endpoints Only This interrupt is valid only when thresholding is enabled. This interrupt is asserted when the core detects an overflow or a CRC error for non-Isochronous OUT packet.
      values as DWC_OTG_INTREG.DOEPINT0.OUTPKTERR
    [6] BACK2BACKSETUP — Back-to-Back SETUP Packets Received (Back2BackSETup) Applies to Control OUT endpoints only. This bit indicates that the core has received more than three back-to-back SETUP packets for this particular endpoint. For information about handling this interrupt,
      values as DWC_OTG_INTREG.DOEPINT0.BACK2BACKSETUP
    [5] STSPHSERCVD — Status Phase Received for Control Write (StsPhseRcvd) This interrupt is valid only for Control OUT endpoints. This interrupt is generated only after the core has transferred all the data that the host has sent during the data phase of a control write transfer, to the system memory buffer. The interrupt indicates to the application that the host has switched from data phase to the status phase of a Control Write transfer. The application can use this interrupt to ACK or STALL the Status phase, after it has decoded the data phase. This is applicable only in Case of Scatter Gather DMA mode.
      values as DWC_OTG_INTREG.DOEPINT0.STSPHSERCVD
    [4] OUTTKNEPDIS — OUT Token Received When Endpoint Disabled (OUTTknEPdis) Applies only to control OUT endpoints. Indicates that an OUT token was received when the endpoint was not yet enabled. This interrupt is asserted on the endpoint for which the OUT token was received.
      values as DWC_OTG_INTREG.DOEPINT0.OUTTKNEPDIS
    [3] SETUP — SETUP Phase Done (SetUp) Applies to control OUT endpoints only. Indicates that the SETUP phase for the control endpoint is complete and no more back-to-back SETUP packets were received for the current control transfer. On this interrupt, the application can decode the received SETUP data packet.
      values as DWC_OTG_INTREG.DOEPINT0.SETUP
    [2] AHBERR — AHB Error (AHBErr) Applies to IN and OUT endpoints. This is generated only in Internal DMA mode when there is an AHB error during an AHB read/write. The application can read the corresponding endpoint DMA address register to get the error address. For details, see 'AHB Error Handling' section in the Programming Guide.
      values as DWC_OTG_INTREG.DIEPINT1.AHBERR
    [1] EPDISBLD — Endpoint Disabled Interrupt (EPDisbld) Applies to IN and OUT endpoints. This bit indicates that the endpoint is disabled per the application's request.
      values as DWC_OTG_INTREG.DIEPINT1.EPDISBLD
    [0] XFERCOMPL — Transfer Completed Interrupt (XferCompl) Applies to IN and OUT endpoints. - When Scatter/Gather DMA mode is enabled -- For IN endpoint this field indicates that the requested data from the descriptor is moved from external system memory to internal FIFO. -- For OUT endpoint this field indicates that the requested data from the internal FIFO is moved to external system memory. This interrupt is generated only when the corresponding endpoint descriptor is closed, and the IOC bit for the corresponding descriptor is Set. - When Scatter/Gather DMA mode is disabled, this field indicates that the programmed transfer is complete on the AHB as well as on the USB, for this endpoint.
      values as DWC_OTG_INTREG.DIEPINT1.XFERCOMPL
  {0xB10+0x20*j} DOEPTSIZ{j} (j=1..8) — This register contains the Transfer Size for the OUT Endpoint {j} of the Device controller.
    [30:29] RXDPID ro — RxDPID Applies to isochronous OUT endpoints only. This is the data PID received in the last packet for this endpoint. - 2'b00: DATA0 - 2'b01: DATA2 - 2'b10: DATA1 - 2'b11: MDATA SETUP Packet Count (SUPCnt) Applies to control OUT Endpoints only. This field specifies the number of back-to-back SETUP data packets the endpoint can receive. - 2'b01: 1 packet - 2'b10: 2 packets - 2'b11: 3 packets
      0=DATA0; 2=DATA1PACKET2 (DATA1 or 2 packets); 1=DATA2PACKET1 (DATA2 or 1 packet); 3=MDATAPACKET3 (MDATA or 3 packets)
    [28:19] PKTCNT — Packet Count (PktCnt) This field is decremented to zero after a packet is written into the RxFIFO.
    [18:0] XFERSIZE — Transfer Size (XferSize) Indicates the transfer size in bytes for endpoint 0. The core interrupts the application only after it has exhausted the transfer size amount of data. The transfer size can be Set to the maximum packet size of the endpoint, to be interrupted at the end of each packet. The core decrements this field every time a packet is read from the RxFIFO and written to the external memory.
  0xE00 PCGCCTL — This register is used to control the Power and Clock Gating characteristics of the controller.
    [7] L1SUSPENDED ro — L1 Deep Sleep Indicates that the PHY is in deep sleep when in L1 state.
      1=ACTIVE (Deep Sleep); 0=INACTIVE (Non Deep Sleep)
    [6] PHYSLEEP ro — PHY In Sleep Indicates that the PHY is in Sleep State.
      1=ACTIVE (Phy in Sleep state); 0=INACTIVE (Phy not in Sleep state)
    [5] ENBL_L1GATING — Enable Sleep Clock Gating If this bit is set, core internal clock gating is enabled sleep state if utmi_l1_suspend_n cannot be asserted by the core. The PHY clock will not be gated in sleep state if Enbl_L1Gating is not set.
      0=DISABLED (The PHY clock is not gated in Sleep state); 1=ENABLED (The Core internal clock gating is enabled in Sleep state)
    [3] RSTPDWNMODULE — Reset Power-Down Modules (RstPdwnModule) This bit is valid only in Partial Power-Down mode. - The application sets this bit when the power is turned off. - The application clears this bit after the power is turned on and the PHY clock is up. Note: The R/W of all core registers are possible only when this bit is set to 1b0.
      1=OFF (Power is turned off); 0=ON (Power is turned on)
    [0] STOPPCLK — Stop Pclk (StopPclk) - The application sets this bit to stop the PHY clock (phy_clk) when the USB is suspended, the session is not valid, or the device is disconnected. - The application clears this bit when the USB is resumed or a new session starts.
      0=DISABLED (Disable Stop Pclk); 1=ENABLED (Enable Stop Pclk)
  0xE04 PCGCCTL1 — This register is used to control the Power and Clock Gating characteristics of the controller.
    [31:4] RSVD ro
    [3] RAMGATEEN — RAM Clock Gating Enable (RAMGateEn) The application programs RAMGateEn to enable RAM Clock Gating in the ACG feature. - 1b0: Disable RAM Clock Gating (Default) - 1b1: Enable RAM Clock Gating
      0=DISABLED (RAM Clock Gating disable); 1=ENABLED (RAM Clock Gating enable)
    [2:1] COUNTER — Count to Gate Clock (CntGateClk) CntGateClk indicates to the Controller how many PHY Clock cycles and AHB Clock cycles of 'IDLE' (no activity) the Controller will wait for before Gating the respective PHY and AHB clocks internal to the Controller. - 2b00: 64 clocks (Default). - 2b01: 128 clocks
      1=CLOCKS128; 0=CLOCKS64
    [0] GATEEN — Enable Active Clock Gating (GateEn) The application programs GateEn to enable Active Clock Gating feature for the PHY and AHB clocks. - 1b0: Disable Active Clock Gating (Default) - 1b1: Enable Active Clock Gating
      0=DISABLED (ACG disable); 1=ENABLED (ACG enable)
